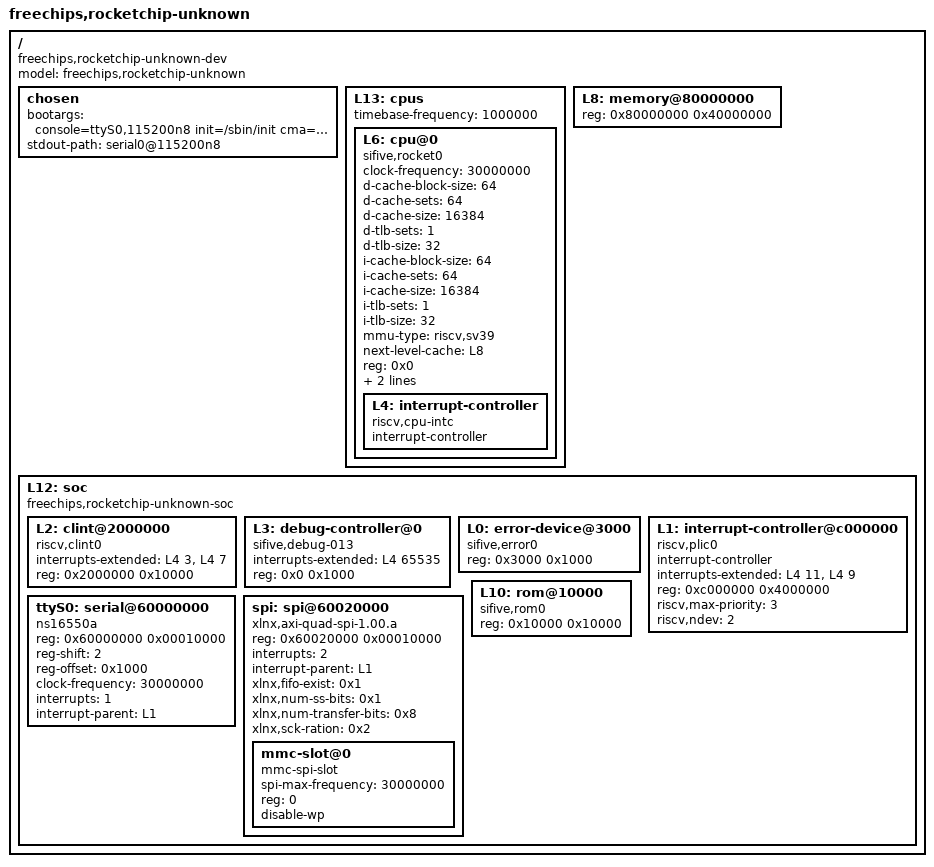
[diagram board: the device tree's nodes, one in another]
/dts-v1/;

/ {
	#address-cells = <1>;
	#size-cells = <1>;
	compatible = "freechips,rocketchip-unknown-dev";
	model = "freechips,rocketchip-unknown";
	
	chosen {
		bootargs = "console=ttyS0,115200n8 init=/sbin/init cma=512M@0-4G";
		stdout-path = "serial0@115200n8";
	};

	L13: cpus {
		#address-cells = <1>;
		#size-cells = <0>;
		timebase-frequency = <1000000>;
		L6: cpu@0 {
			clock-frequency = <30000000>;
			compatible = "sifive,rocket0", "riscv";
			d-cache-block-size = <64>;
			d-cache-sets = <64>;
			d-cache-size = <16384>;
			d-tlb-sets = <1>;
			d-tlb-size = <32>;
			device_type = "cpu";
			i-cache-block-size = <64>;
			i-cache-sets = <64>;
			i-cache-size = <16384>;
			i-tlb-sets = <1>;
			i-tlb-size = <32>;
			mmu-type = "riscv,sv39";
			next-level-cache = <&L8>;
			reg = <0x0>;
			riscv,isa = "rv64imafdc";
			status = "okay";
			tlb-split;
			L4: interrupt-controller {
				#interrupt-cells = <1>;
				compatible = "riscv,cpu-intc";
				interrupt-controller;
			};
		};
	};
	L8: memory@80000000 {
		device_type = "memory";
		reg = <0x80000000 0x40000000>;
	};
	L12: soc {
		#address-cells = <1>;
		#size-cells = <1>;
		compatible = "freechips,rocketchip-unknown-soc", "simple-bus";
		ranges;
		L2: clint@2000000 {
			compatible = "riscv,clint0";
			interrupts-extended = <&L4 3 &L4 7>;
			reg = <0x2000000 0x10000>;
			reg-names = "control";
		};
		L3: debug-controller@0 {
			compatible = "sifive,debug-013", "riscv,debug-013";
			interrupts-extended = <&L4 65535>;
			reg = <0x0 0x1000>;
			reg-names = "control";
		};
		L0: error-device@3000 {
			compatible = "sifive,error0";
			reg = <0x3000 0x1000>;
		};
		L1: interrupt-controller@c000000 {
			#interrupt-cells = <1>;
			compatible = "riscv,plic0";
			interrupt-controller;
			interrupts-extended = <&L4 11 &L4 9>;
			reg = <0xc000000 0x4000000>;
			reg-names = "control";
			riscv,max-priority = <3>;
			riscv,ndev = <2>;
		};

		ttyS0: serial@60000000 {
			compatible = "ns16550a";
			reg = <0x60000000 0x00010000>;
			
			reg-shift = <2>;
			reg-offset = <0x1000>;

			device_type = "serial";
			clock-frequency = <30000000>;
 			
 			interrupts = <1>;
			interrupt-parent = <&L1>;
		};

		spi: spi@60020000 {
			compatible = "xlnx,axi-quad-spi-1.00.a";
			status = "okay";
			reg = <0x60020000 0x00010000>;
			interrupts = <2>;
			interrupt-parent = <&L1>;
			xlnx,fifo-exist = <0x1>;
			xlnx,num-ss-bits = <0x1>;
			xlnx,num-transfer-bits = <0x8>;
			xlnx,sck-ration = <0x2>;
			mmc-slot@0 {
				spi-max-frequency = <30000000>;
				compatible = "mmc-spi-slot";
				reg = <0>;
				disable-wp;
//				mmc2_pwrseq@0 {
//       			compatible = "mmc-pwrseq-simple";
//        			reset-gpios = <&spi 0 1>;
//				};
			};
		};
		
		L10: rom@10000 {
			compatible = "sifive,rom0";
			reg = <0x10000 0x10000>;
			reg-names = "mem";
		};
	};
};
